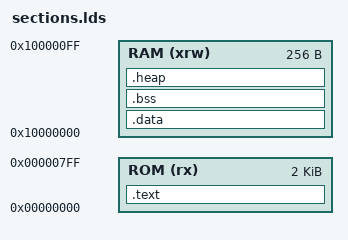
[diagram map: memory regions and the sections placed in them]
MEMORY
{
    ROM (rx)        : ORIGIN = 0x00000000, LENGTH = 0x000800 /* 2 kiB */
    RAM (xrw)       : ORIGIN = 0x10000000, LENGTH = 0x000100 /* 256 B */
}

SECTIONS {
    /* The program code and other data goes into ROM */
    .text :
    {
        . = ALIGN(4);
        *(.text)           /* .text sections (code) */
        *(.text*)          /* .text* sections (code) */
    } >ROM

    .data :
    {
       . = ALIGN(4);
        *(.data)           /* .data sections */
        *(.data*)          /* .data* sections */
        *(.sdata)           /* .sdata sections */
        *(.sdata*)          /* .sdata* sections */
	  } >RAM

    /* Uninitialized data section */
    .bss :
    {
        . = ALIGN(4);
        _sbss = .;         /* define a global symbol at bss start; used by startup code */
        *(.bss)
        *(.bss*)
        *(.sbss)
        *(.sbss*)
        *(COMMON)

         } >RAM

    /* this is to define the start of the heap, and make sure we have a minimum size */
    .heap :
    {
        . = ALIGN(4);
        _heap_start = .;    /* define a global symbol at heap start */
    } >RAM
}
